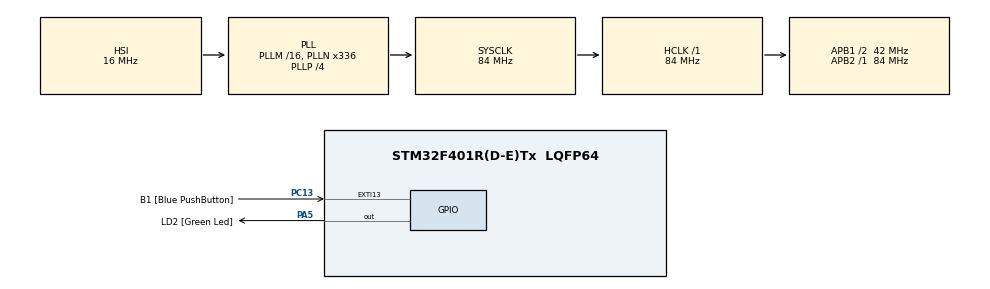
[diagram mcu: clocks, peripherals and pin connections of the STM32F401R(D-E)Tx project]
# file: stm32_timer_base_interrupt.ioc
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Mcu.Family=STM32F4
Mcu.Name=STM32F401R(D-E)Tx
Mcu.Package=LQFP64
NVIC.EXTI15_10_IRQn=true\:0\:0\:false\:false\:true\:true\:true\:true
NVIC.PriorityGroup=NVIC_PRIORITYGROUP_4
NVIC.TIM2_IRQn=true\:0\:0\:false\:false\:true\:true\:true\:true
PA13.GPIO_Label=TMS
PA13.Signal=SYS_JTMS-SWDIO
PA5.GPIO_Label=LD2 [Green Led]
PA5.GPIO_Mode=GPIO_MODE_OUTPUT_PP
PA5.GPIO_PuPd=GPIO_NOPULL
PA5.GPIO_Speed=GPIO_SPEED_FREQ_MEDIUM
PA5.Signal=GPIO_Output
PC13-ANTI_TAMP.GPIO_Label=B1 [Blue PushButton]
PC13-ANTI_TAMP.GPIO_ModeDefaultEXTI=GPIO_MODE_IT_FALLING
PC13-ANTI_TAMP.GPIO_PuPd=GPIO_NOPULL
PC13-ANTI_TAMP.Signal=GPXTI13
PH0\ -\ OSC_IN.Mode=HSE-External-Clock-Source
PH0\ -\ OSC_IN.Signal=RCC_OSC_IN
PH1\ -\ OSC_OUT.Mode=HSE-External-Clock-Source
PH1\ -\ OSC_OUT.Signal=RCC_OSC_OUT
ProjectManager.HeapSize=0x200
ProjectManager.StackSize=0x400
ProjectManager.TargetToolchain=STM32CubeIDE
RCC.48MHZClocksFreq_Value=48000000
RCC.AHBFreq_Value=84000000
RCC.APB1CLKDivider=RCC_HCLK_DIV2
RCC.APB1Freq_Value=42000000
RCC.APB1TimFreq_Value=84000000
RCC.APB2Freq_Value=84000000
RCC.APB2TimFreq_Value=84000000
RCC.CortexFreq_Value=84000000
RCC.HCLKFreq_Value=84000000
RCC.HSE_VALUE=8000000
RCC.HSI_VALUE=16000000
RCC.PLLN=336
RCC.PLLP=RCC_PLLP_DIV4
RCC.PLLQ=7
RCC.SYSCLKFreq_VALUE=84000000
RCC.SYSCLKSource=RCC_SYSCLKSOURCE_PLLCLK
RCC.VCOOutputFreq_Value=336000000
TIM2.Prescaler=8399
VP_TIM2_VS_ClockSourceINT.Mode=Internal
board=NUCLEO-F401RE

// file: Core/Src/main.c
/**************************** main.c ****************************/
/* USER CODE BEGIN Header */
/**
  ******************************************************************************
  * @file           : main.c
  * @brief          : Main program body
  ******************************************************************************
  * @attention
  *
  * Copyright (c) 2026 STMicroelectronics.
  * All rights reserved.
  *
  * This software is licensed under terms that can be found in the LICENSE file
  * in the root directory of this software component.
  * If no LICENSE file comes with this software, it is provided AS-IS.
  *
  ******************************************************************************
  */
/* USER CODE END Header */
#include "main.h"

TIM_HandleTypeDef htim2;

/* USER CODE BEGIN PV */
static volatile uint32_t g_ms = 0;
static volatile uint8_t  g_run = 1;          // 버튼으로 ON/OFF 토글(선택)
static const uint32_t    LED_PERIOD_MS = 500; // 500ms마다 토글
/* USER CODE END PV */

void SystemClock_Config(void);
static void MX_GPIO_Init(void);
static void MX_TIM2_Init(void);

/* USER CODE BEGIN 0 */

/**
  * @brief TIM 주기 인터럽트 콜백 (HAL이 TIM2 업데이트 이벤트마다 호출)
  */
void HAL_TIM_PeriodElapsedCallback(TIM_HandleTypeDef *htim)
{
  if (htim->Instance == TIM2)
  {
    g_ms++;

    if (g_run && (g_ms % LED_PERIOD_MS == 0))
    {
      HAL_GPIO_TogglePin(LD2_GPIO_Port, LD2_Pin);
    }
  }
}

/**
  * @brief EXTI 콜백(보드 USER 버튼 눌렀을 때)
  *        - 선택 기능: LED 토글 동작을 ON/OFF
  */
void HAL_GPIO_EXTI_Callback(uint16_t GPIO_Pin)
{
  if (GPIO_Pin == B1_Pin)
  {
    g_run ^= 1U; // 동작 토글
  }
}

/* USER CODE END 0 */

int main(void)
{

  /* MCU Configuration--------------------------------------------------------*/
  HAL_Init();

  SystemClock_Config();

  MX_GPIO_Init();
  MX_TIM2_Init();

  /* USER CODE BEGIN 2 */
  // TIM2 업데이트 인터럽트 시작 (이거 없으면 인터럽트 안 뜸)
  if (HAL_TIM_Base_Start_IT(&htim2) != HAL_OK)
  {
    Error_Handler();
  }
  /* USER CODE END 2 */

  /* Infinite loop */
  while (1)
  {

    /* USER CODE BEGIN 3 */
    // 메인 루프는 비워둠: 시간 기반 동작은 타이머 ISR이 수행
  }
  /* USER CODE END 3 */
}

void SystemClock_Config(void)
{
  RCC_OscInitTypeDef RCC_OscInitStruct = {0};
  RCC_ClkInitTypeDef RCC_ClkInitStruct = {0};

  /** Configure the main internal regulator output voltage */
  __HAL_RCC_PWR_CLK_ENABLE();
  __HAL_PWR_VOLTAGESCALING_CONFIG(PWR_REGULATOR_VOLTAGE_SCALE2);

  /** Initializes the RCC Oscillators according to the specified parameters */
  RCC_OscInitStruct.OscillatorType = RCC_OSCILLATORTYPE_HSI;
  RCC_OscInitStruct.HSIState = RCC_HSI_ON;
  RCC_OscInitStruct.HSICalibrationValue = RCC_HSICALIBRATION_DEFAULT;
  RCC_OscInitStruct.PLL.PLLState = RCC_PLL_ON;
  RCC_OscInitStruct.PLL.PLLSource = RCC_PLLSOURCE_HSI;
  RCC_OscInitStruct.PLL.PLLM = 16;
  RCC_OscInitStruct.PLL.PLLN = 336;
  RCC_OscInitStruct.PLL.PLLP = RCC_PLLP_DIV4;
  RCC_OscInitStruct.PLL.PLLQ = 7;
  if (HAL_RCC_OscConfig(&RCC_OscInitStruct) != HAL_OK)
  {
    Error_Handler();
  }

  /** Initializes the CPU, AHB and APB buses clocks */
  RCC_ClkInitStruct.ClockType = RCC_CLOCKTYPE_HCLK|RCC_CLOCKTYPE_SYSCLK
                              |RCC_CLOCKTYPE_PCLK1|RCC_CLOCKTYPE_PCLK2;
  RCC_ClkInitStruct.SYSCLKSource = RCC_SYSCLKSOURCE_PLLCLK;
  RCC_ClkInitStruct.AHBCLKDivider = RCC_SYSCLK_DIV1;
  RCC_ClkInitStruct.APB1CLKDivider = RCC_HCLK_DIV2;
  RCC_ClkInitStruct.APB2CLKDivider = RCC_HCLK_DIV1;

  if (HAL_RCC_ClockConfig(&RCC_ClkInitStruct, FLASH_LATENCY_2) != HAL_OK)
  {
    Error_Handler();
  }
}

static void MX_TIM2_Init(void)
{
  TIM_ClockConfigTypeDef sClockSourceConfig = {0};
  TIM_MasterConfigTypeDef sMasterConfig = {0};

  htim2.Instance = TIM2;
  htim2.Init.Prescaler = 8399;
  htim2.Init.CounterMode = TIM_COUNTERMODE_UP;
  htim2.Init.Period = 9; // 1ms tick
  htim2.Init.ClockDivision = TIM_CLOCKDIVISION_DIV1;
  htim2.Init.AutoReloadPreload = TIM_AUTORELOAD_PRELOAD_DISABLE;

  if (HAL_TIM_Base_Init(&htim2) != HAL_OK)
  {
    Error_Handler();
  }

  sClockSourceConfig.ClockSource = TIM_CLOCKSOURCE_INTERNAL;
  if (HAL_TIM_ConfigClockSource(&htim2, &sClockSourceConfig) != HAL_OK)
  {
    Error_Handler();
  }

  sMasterConfig.MasterOutputTrigger = TIM_TRGO_RESET;
  sMasterConfig.MasterSlaveMode = TIM_MASTERSLAVEMODE_DISABLE;
  if (HAL_TIMEx_MasterConfigSynchronization(&htim2, &sMasterConfig) != HAL_OK)
  {
    Error_Handler();
  }

  /* USER CODE BEGIN TIM2_Init 2 */
  // NVIC에서 TIM2 IRQ 활성화 (CubeMX에서 이미 켜면 중복이어도 보통 문제 없음)
  HAL_NVIC_SetPriority(TIM2_IRQn, 1, 0);
  HAL_NVIC_EnableIRQ(TIM2_IRQn);
  /* USER CODE END TIM2_Init 2 */
}

static void MX_GPIO_Init(void)
{
  GPIO_InitTypeDef GPIO_InitStruct = {0};

  __HAL_RCC_GPIOC_CLK_ENABLE();
  __HAL_RCC_GPIOH_CLK_ENABLE();
  __HAL_RCC_GPIOA_CLK_ENABLE();

  /*Configure GPIO pin Output Level */
  HAL_GPIO_WritePin(LD2_GPIO_Port, LD2_Pin, GPIO_PIN_RESET);

  /*Configure GPIO pin : B1_Pin */
  GPIO_InitStruct.Pin = B1_Pin;
  GPIO_InitStruct.Mode = GPIO_MODE_IT_FALLING;
  GPIO_InitStruct.Pull = GPIO_NOPULL;
  HAL_GPIO_Init(B1_GPIO_Port, &GPIO_InitStruct);

  /*Configure GPIO pin : LD2_Pin */
  GPIO_InitStruct.Pin = LD2_Pin;
  GPIO_InitStruct.Mode = GPIO_MODE_OUTPUT_PP;
  GPIO_InitStruct.Pull = GPIO_NOPULL;
  GPIO_InitStruct.Speed = GPIO_SPEED_FREQ_MEDIUM;
  HAL_GPIO_Init(LD2_GPIO_Port, &GPIO_InitStruct);

  /* EXTI interrupt init*/
  HAL_NVIC_SetPriority(EXTI15_10_IRQn, 0, 0);
  HAL_NVIC_EnableIRQ(EXTI15_10_IRQn);
}

void Error_Handler(void)
{
  __disable_irq();
  while (1)
  {
  }
}
